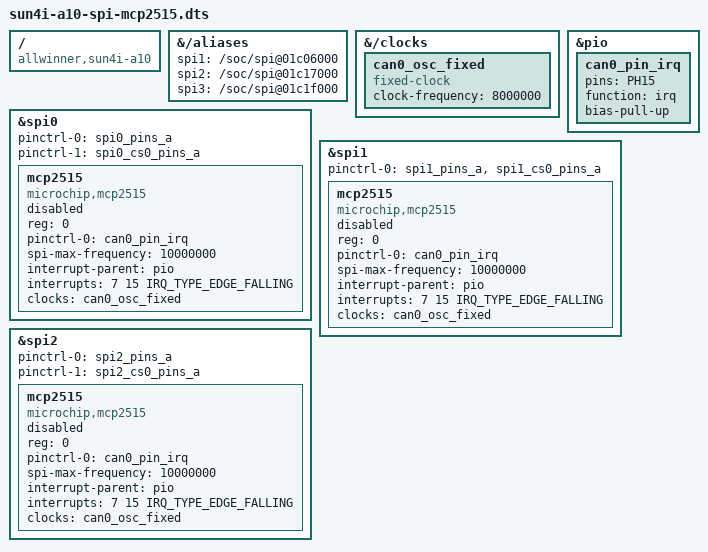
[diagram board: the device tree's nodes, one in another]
/dts-v1/;
/plugin/;

#include <dt-bindings/interrupt-controller/irq.h>

/ {
	compatible = "allwinner,sun4i-a10";

	fragment@0 {
		target-path = "/aliases";
		__overlay__ {
			spi1 = "/soc/spi@01c06000";
			spi2 = "/soc/spi@01c17000";
			spi3 = "/soc/spi@01c1f000";
		};
	};

	fragment@1 {
		target-path = "/clocks";
		__overlay__ {
			#address-cells = <1>;
			#size-cells = <1>;
			can0_osc_fixed: can0_osc_fixed {
				compatible = "fixed-clock";
				#clock-cells = <0>;
				clock-frequency  = <8000000>;
			};
		};
	};

	fragment@2 {
		target = <&pio>;
		__overlay__ {
			can0_pin_irq: can0_pin_irq {
				pins = "PH15";
				function = "irq";
				bias-pull-up;
			};
		};
	};

	fragment@3 {
		target = <&spi0>;
		__overlay__ {
			pinctrl-names = "default", "default";
			pinctrl-0 = <&spi0_pins_a>;
			pinctrl-1 = <&spi0_cs0_pins_a>;
			#address-cells = <1>;
			#size-cells = <0>;
			mcp2515 {
				reg = <0>;
				compatible = "microchip,mcp2515";
				pinctrl-names = "default";
				pinctrl-0 = <&can0_pin_irq>;
				spi-max-frequency = <10000000>;
				interrupt-parent = <&pio>;
				interrupts = <7 15 IRQ_TYPE_EDGE_FALLING>; /* PH15 */
				clocks = <&can0_osc_fixed>;
				status = "disabled";
			};
		};
	};

	fragment@4 {
		target = <&spi1>;
		__overlay__ {
			pinctrl-names = "default";
			pinctrl-0 = <&spi1_pins_a>, <&spi1_cs0_pins_a>;
			#address-cells = <1>;
			#size-cells = <0>;
			mcp2515 {
				reg = <0>;
				compatible = "microchip,mcp2515";
				pinctrl-names = "default";
				pinctrl-0 = <&can0_pin_irq>;
				spi-max-frequency = <10000000>;
				interrupt-parent = <&pio>;
				interrupts = <7 15 IRQ_TYPE_EDGE_FALLING>; /* PH15 */
				clocks = <&can0_osc_fixed>;
				status = "disabled";
			};
		};
	};

	fragment@5 {
		target = <&spi2>;
		__overlay__ {
			pinctrl-names = "default", "default";
			pinctrl-0 = <&spi2_pins_a>;
			pinctrl-1 = <&spi2_cs0_pins_a>;
			#address-cells = <1>;
			#size-cells = <0>;
			mcp2515 {
				reg = <0>;
				compatible = "microchip,mcp2515";
				pinctrl-names = "default";
				pinctrl-0 = <&can0_pin_irq>;
				spi-max-frequency = <10000000>;
				interrupt-parent = <&pio>;
				interrupts = <7 15 IRQ_TYPE_EDGE_FALLING>; /* PH15 */
				clocks = <&can0_osc_fixed>;
				status = "disabled";
			};
		};
	};
};
